# CY8C4245AXI_483 register map
File version: 0.1
PSoC 4200
Registers are 8-bit, read-write, no defined reset value unless marked. A register's access mark holds for its fields unless they carry their own. Offsets are from the block's base; lines under a group give offsets from that group; [hi:lo] are bit positions; {n}, {i} and the like mark numbered series; 'fields as' and 'values as' point back to an identical list; <NAME> marks a mode.

## Memory map
0x00000000 Timer_Duration
0x00000000 Timer_Main
0x00000000 IDAC_1 — IDAC

## Timer_Duration
Base 0x00000000
0x400F0000 Timer_Duration_COUNTER 16-bit — UDB.A0 - Current Down Counter Value
0x400F0020 Timer_Duration_PERIOD 16-bit — UDB.D0 - Assigned Period
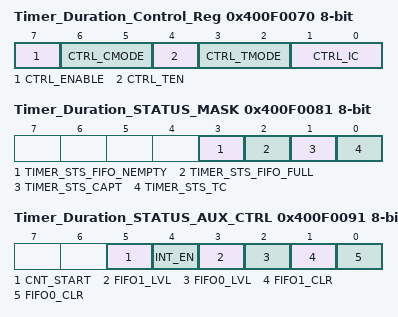
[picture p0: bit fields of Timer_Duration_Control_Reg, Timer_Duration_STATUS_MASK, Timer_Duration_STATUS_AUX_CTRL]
0x400F0070 Timer_Duration_Control_Reg — UDB Control Register - Assigned Control Register Value
  [7] CTRL_ENABLE — Enable the Timer
  [6:5] CTRL_CMODE — Capture Mode
  [4] CTRL_TEN — Trigger Enable Bit
  [3:2] CTRL_TMODE — Trigger Mode
  [1:0] CTRL_IC — Interrupt Count
0x400F0081 Timer_Duration_STATUS_MASK — UDB Status bits Interrupt Mask Enable Register
  [3] TIMER_STS_FIFO_NEMPTY ro — FIFO Empty status
  [2] TIMER_STS_FIFO_FULL ro — FIFO Full Status
  [1] TIMER_STS_CAPT ro — Enables the Interrupt on Capture
  [0] TIMER_STS_TC ro — Enables the Interrupt on TC
0x400F0091 Timer_Duration_STATUS_AUX_CTRL — UDB Auxilliary Control Register
  [5] CNT_START — FIFO0 clear
    0=E_CNT_START0 (Disable counter); 1=E_CNT_START1 (Enable counter)
  [4] INT_EN
    0=E_INT_EN0 (Interrupt disabled); 1=E_INT_EN1 (Interrupt enabled)
  [3] FIFO1_LVL — FIFO level
    0=E_FIFO_LVL_0 (FIFO LVL: input mode: FIFO not full; output mode: FIFO not empty); 1=E_FIFO_LVL_1 (FIFO LVL: input mode: FIFO at least 1/2 empty; output mode: FIFO at least 1/2 full)
  [2] FIFO0_LVL — FIFO level
    values as FIFO1_LVL
  [1] FIFO1_CLR — FIFO1 clear
    0=E_FIFO_CLR_0 (Normal FIFO operation); 1=E_FIFO_CLR_1 (Clear FIFO state)
  [0] FIFO0_CLR — FIFO0 clear
    values as FIFO1_CLR

## Timer_Main
Base 0x00000000
0x400F0002 Timer_Main_COUNTER 16-bit — UDB.A0 - Current Down Counter Value
0x400F0022 Timer_Main_PERIOD 16-bit — UDB.D0 - Assigned Period
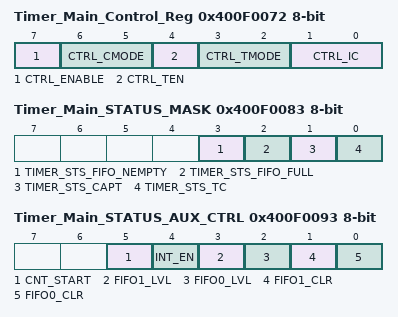
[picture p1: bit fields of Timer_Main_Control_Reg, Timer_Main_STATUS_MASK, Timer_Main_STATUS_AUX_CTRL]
0x400F0072 Timer_Main_Control_Reg — UDB Control Register - Assigned Control Register Value
  [7] CTRL_ENABLE — Enable the Timer
  [6:5] CTRL_CMODE — Capture Mode
  [4] CTRL_TEN — Trigger Enable Bit
  [3:2] CTRL_TMODE — Trigger Mode
  [1:0] CTRL_IC — Interrupt Count
0x400F0083 Timer_Main_STATUS_MASK — UDB Status bits Interrupt Mask Enable Register
  fields as Timer_Duration.Timer_Duration_STATUS_MASK
0x400F0093 Timer_Main_STATUS_AUX_CTRL — UDB Auxilliary Control Register
  fields as Timer_Duration.Timer_Duration_STATUS_AUX_CTRL

## IDAC_1 — IDAC
Base 0x00000000
0x40080004 CSD_IDAC_POLARITY 32-bit
0x40080008 CSD_IDAC 32-bit
0x4008FF00 CSD_TRIM1 32-bit — CSD IDAC TRIM1
0x4008FF04 CSD_TRIM2 32-bit — CSD IDAC TRIM2
